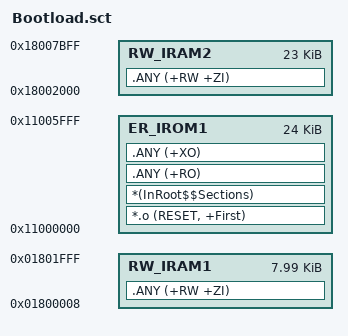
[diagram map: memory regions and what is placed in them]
; *************************************************************
; *** Scatter-Loading Description File generated by uVision ***
; *************************************************************

LR_IROM1 0x11000000 0x00006000  {    ; load region size_region
  ER_IROM1 0x11000000 0x00006000  {  ; load address = execution address
   *.o (RESET, +First)
   *(InRoot$$Sections)
   .ANY (+RO)
   .ANY (+XO)
  }
  RW_IRAM1 0x01800008 0x00001FF8  {  ; RW data
   .ANY (+RW +ZI)
  }
  RW_IRAM2 0x18002000 0x00005C00  {
   .ANY (+RW +ZI)
  }
}

